# SF32LB57x register map
File version: 1.0
CPU: CM33 r0p1, little endian, MPU, FPU, 3 interrupt priority bits
Registers are 32-bit, read-write, reset 0x0 unless marked. A register's access mark holds for its fields unless they carry their own. Offsets are from the block's base; [hi:lo] are bit positions; {n}, {i} and the like mark numbered series.

## PTC2
Base 0x4000C000
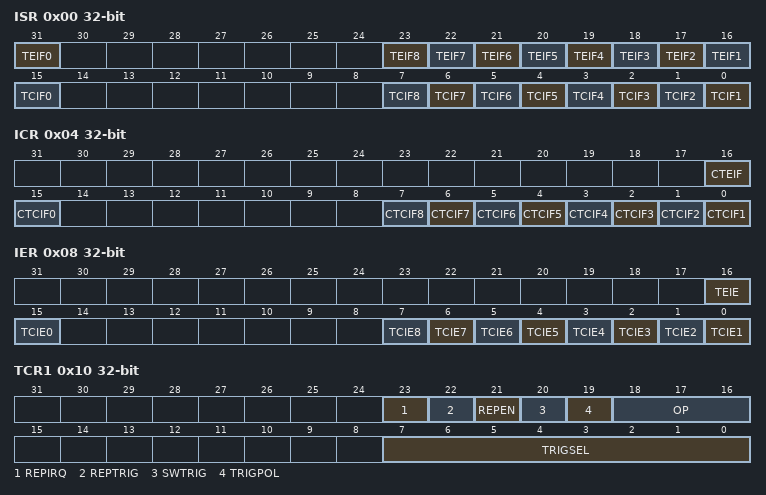
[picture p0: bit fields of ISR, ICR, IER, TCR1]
0x00 ISR — interrupt status register
  [31] TEIF0 — transfer error flag for task 0
  [n+15] TEIF{n} (n=1..8) — transfer error flag for task {n}
  [15] TCIF0 — task complete interrupt flag for task 0
  [n-1] TCIF{n} (n=1..8) — task complete interrupt flag for task {n}
0x04 ICR — interrupt clear register
  [16] CTEIF — clear transfer error flag
  [15] CTCIF0 — clear task complete interrupt flag for task 0
  [n-1] CTCIF{n} (n=1..8) — clear task complete interrupt flag for task {n}
0x08 IER — interrupt enable register
  [16] TEIE — enable transfer error flag
  [15] TCIE0 — enable task complete interrupt for task 0
  [n-1] TCIE{n} (n=1..8) — enable task complete interrupt for task {n}
0x10 TCR1 — task 1 control register
  [23] REPIRQ — repetition interrupt 0: interrupt will be generated after each operation 1: interrupt will be generated after operation for REP times
  [22] REPTRIG — repetition trigger 0: ptc trigger will be generated after each operation 1: ptc trigger will be generated after operation for REP times
  [21] REPEN — repetition enable 0: task will be triggerd no matter what value REP is 1: task will only be triggerd when REP is not 0
  [20] SWTRIG — software trigger task will be triggerd at once after SWTRIG set. SWTRIG will be cleared automatically.
  [19] TRIGPOL — trigger polarity 0: select positive edge of trigger 1: select negative edge of trigger
  [18:16] OP — task operation 3'b000: direct write data 3'b100: read then XOR with data and write back 3'b101: read then OR with data and write back 3'b110: read then AND with data and write back 3'b111: read then add with data and write back
  [7:0] TRIGSEL — select trigger source 0: task will only be triggered by SWTRIG others: task will be triggered by selected source or SWTRIG
0x14 TAR1 — task 1 address register
  [31:0] ADDR — peripheral address to access to
0x18 TDR1 — task 1 data register
  [31:0] DATA — data value for task operation
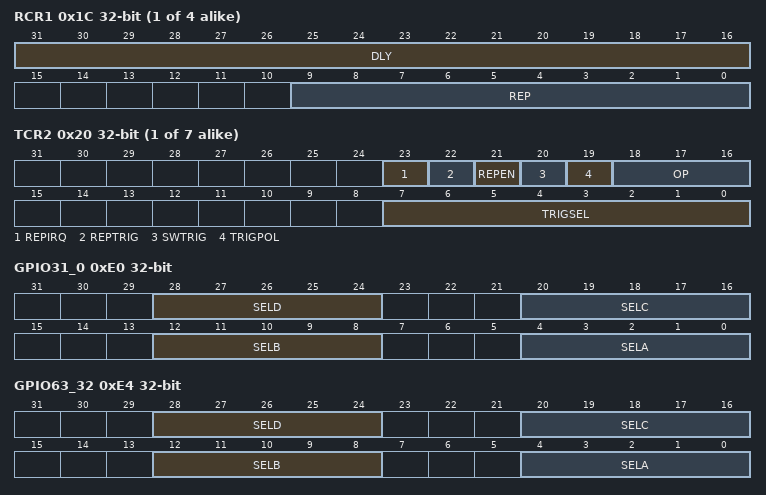
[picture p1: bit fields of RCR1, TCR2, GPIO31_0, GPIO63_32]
{0xC+0x10*i} RCR{i} (i=1..4) — task {i} repetition and delay counter register
  [31:16] DLY — Delay time before task operation after triggered 0: no delay others: delay DLY HCLK cycles before task operation DLY is read as left delay time. DLY will be reloaded automatically after each operation.
  [9:0] REP — Repetition counter value if REPEN is 1, task will only be triggerd when REP is not 0. when REP is larger than 0, it will be decrease by 1 automatically each time task triggered.
{0x0+0x10*i} TCR{i} (i=2..8)
  [23] REPIRQ — repetition interrupt 0: interrupt will be generated after each operation 1: interrupt will be generated after operation for REP times
  [22] REPTRIG — repetition trigger 0: ptc trigger will be generated after each operation 1: ptc trigger will be generated after operation for REP times
  [21] REPEN — repetition enable 0: task will be triggerd no matter what value REP is 1: task will only be triggerd when REP is not 0
  [20] SWTRIG — software trigger task will be triggerd at once after SWTRIG set. SWTRIG will be cleared automatically.
  [19] TRIGPOL — trigger polarity 0: select positive edge of trigger 1: select negative edge of trigger
  [18:16] OP — task operation 3'b000: direct write data 3'b100: read then XOR with data and write back 3'b101: read then OR with data and write back 3'b110: read then AND with data and write back 3'b111: read then add with data and write back
  [7:0] TRIGSEL — select trigger source
{0x4+0x10*i} TAR{i} (i=2..8)
  [31:0] ADDR — peripheral address to access to
{0x8+0x10*i} TDR{i} (i=2..8)
  [31:0] DATA — data value for task operation
{0xC+0x10*i} RCR{i} (i=5..8) — task {i} repetition counter register
  [9:0] REP — Repetition counter value if REPEN is 1, task will only be triggerd when REP is not 0. when REP is larger than 0, it will be decrease by 1 automatically each time task triggered.
{0xCC+4i} MEM{i} (i=1..4) — temporary memory {i}
  [31:0] DATA — memory to store temporary variables
0xE0 GPIO31_0
  [28:24] SELD — select trigger D of GPIO 31~0
  [20:16] SELC — select trigger C of GPIO 31~0
  [12:8] SELB — select trigger B of GPIO 31~0
  [4:0] SELA — select trigger A of GPIO 31~0 0: select GPIO 0 1: select GPIO 1 …… 31: select GPIO 31
0xE4 GPIO63_32
  [28:24] SELD — select trigger D of GPIO 63~32
  [20:16] SELC — select trigger C of GPIO 63~32
  [12:8] SELB — select trigger B of GPIO 63~32
  [4:0] SELA — select trigger A of GPIO 63~32 0: select GPIO 32 1: select GPIO 33 …… 31: select GPIO 63
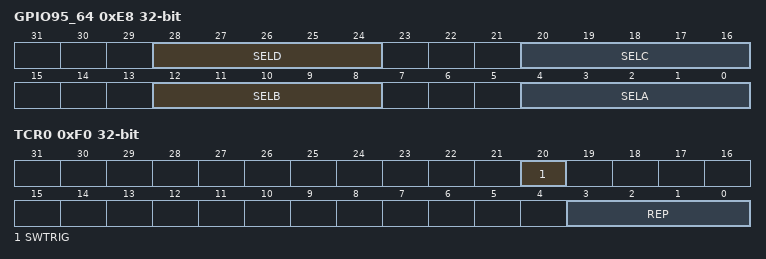
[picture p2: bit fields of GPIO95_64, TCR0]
0xE8 GPIO95_64
  [28:24] SELD — select trigger D of GPIO 95~64
  [20:16] SELC — select trigger C of GPIO 95~64
  [12:8] SELB — select trigger B of GPIO 95~64
  [4:0] SELA — select trigger A of GPIO 95~64 0: select GPIO 64 1: select GPIO 65 …… 31: select GPIO 95
0xF0 TCR0 — task 0 (security task) control register
  [20] SWTRIG — software trigger task will be triggerd at once after SWTRIG set. SWTRIG will be cleared automatically.
  [3:0] REP — Repetition counter value task will only be triggerd when REP is not 0. when REP is larger than 0, it will be decrease by 1 automatically each time task triggered.
